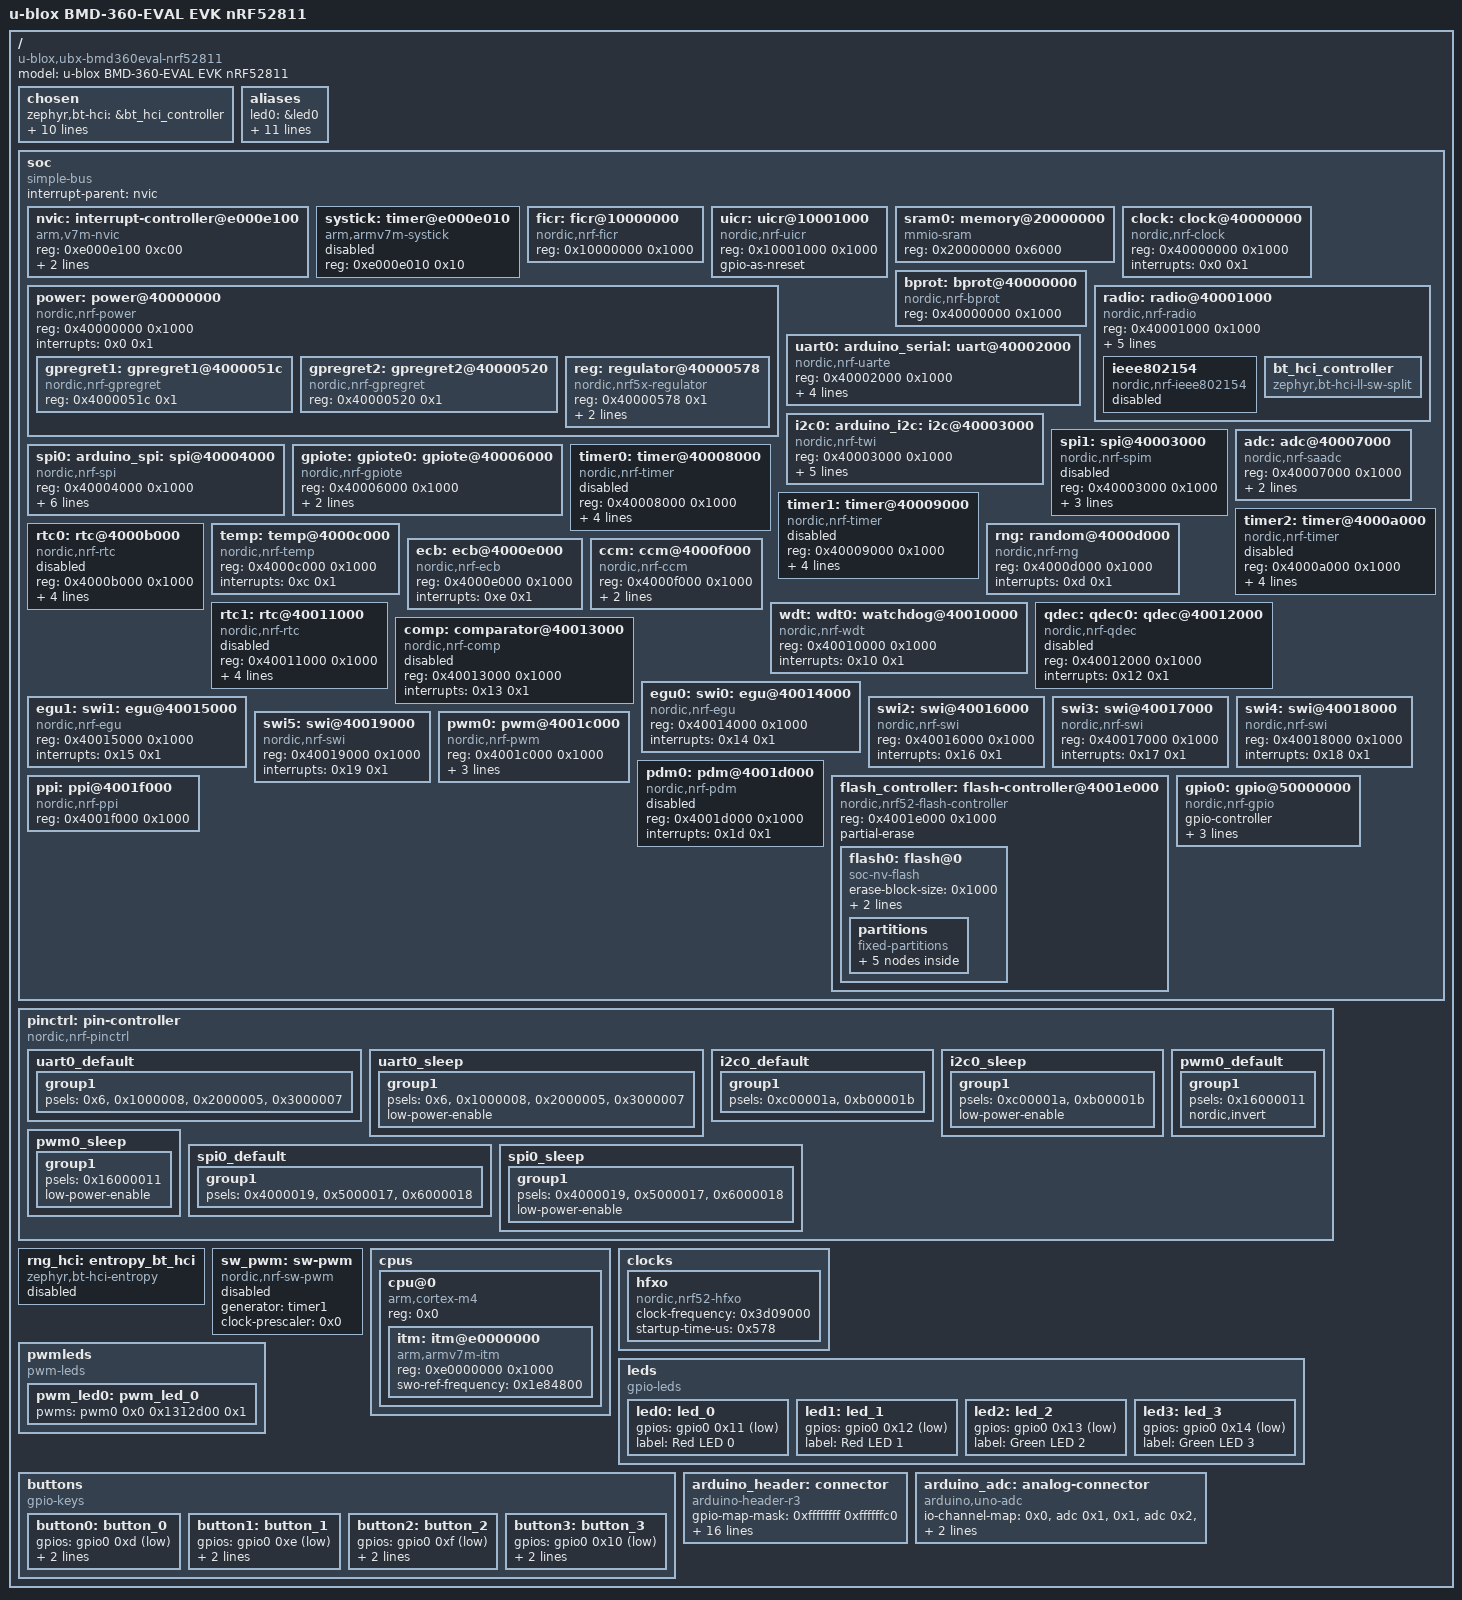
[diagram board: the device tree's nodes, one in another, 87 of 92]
/dts-v1/;

/* node '/' defined in zephyr/dts/common/skeleton.dtsi:9 */
/ {
	#address-cells = < 0x1 >;                      /* in zephyr/dts/common/skeleton.dtsi:10 */
	#size-cells = < 0x1 >;                         /* in zephyr/dts/common/skeleton.dtsi:11 */
	model = "u-blox BMD-360-EVAL EVK nRF52811";    /* in zephyr/boards/u-blox/ubx_bmd360eval/ubx_bmd360eval_nrf52811.dts:14 */
	compatible = "u-blox,ubx-bmd360eval-nrf52811"; /* in zephyr/boards/u-blox/ubx_bmd360eval/ubx_bmd360eval_nrf52811.dts:15 */

	/* node '/chosen' defined in zephyr/dts/common/skeleton.dtsi:13 */
	chosen {
		zephyr,bt-hci = &bt_hci_controller;          /* in zephyr/dts/arm/nordic/nrf52811.dtsi:14 */
		zephyr,entropy = &rng;                       /* in zephyr/dts/arm/nordic/nrf52811.dtsi:15 */
		zephyr,flash-controller = &flash_controller; /* in zephyr/dts/arm/nordic/nrf52811.dtsi:16 */
		zephyr,console = &uart0;                     /* in zephyr/boards/u-blox/ubx_bmd360eval/ubx_bmd360eval_nrf52811.dts:18 */
		zephyr,shell-uart = &uart0;                  /* in zephyr/boards/u-blox/ubx_bmd360eval/ubx_bmd360eval_nrf52811.dts:19 */
		zephyr,uart-mcumgr = &uart0;                 /* in zephyr/boards/u-blox/ubx_bmd360eval/ubx_bmd360eval_nrf52811.dts:20 */
		zephyr,bt-mon-uart = &uart0;                 /* in zephyr/boards/u-blox/ubx_bmd360eval/ubx_bmd360eval_nrf52811.dts:21 */
		zephyr,bt-c2h-uart = &uart0;                 /* in zephyr/boards/u-blox/ubx_bmd360eval/ubx_bmd360eval_nrf52811.dts:22 */
		zephyr,sram = &sram0;                        /* in zephyr/boards/u-blox/ubx_bmd360eval/ubx_bmd360eval_nrf52811.dts:23 */
		zephyr,flash = &flash0;                      /* in zephyr/boards/u-blox/ubx_bmd360eval/ubx_bmd360eval_nrf52811.dts:24 */
		zephyr,code-partition = &slot0_partition;    /* in zephyr/boards/u-blox/ubx_bmd360eval/ubx_bmd360eval_nrf52811.dts:25 */
	};

	/* node '/aliases' defined in zephyr/dts/common/skeleton.dtsi:15 */
	aliases {
		led0 = &led0;               /* in zephyr/boards/u-blox/ubx_bmd360eval/ubx_bmd360eval_nrf52811.dts:130 */
		led1 = &led1;               /* in zephyr/boards/u-blox/ubx_bmd360eval/ubx_bmd360eval_nrf52811.dts:131 */
		led2 = &led2;               /* in zephyr/boards/u-blox/ubx_bmd360eval/ubx_bmd360eval_nrf52811.dts:132 */
		led3 = &led3;               /* in zephyr/boards/u-blox/ubx_bmd360eval/ubx_bmd360eval_nrf52811.dts:133 */
		pwm-led0 = &pwm_led0;       /* in zephyr/boards/u-blox/ubx_bmd360eval/ubx_bmd360eval_nrf52811.dts:134 */
		sw0 = &button0;             /* in zephyr/boards/u-blox/ubx_bmd360eval/ubx_bmd360eval_nrf52811.dts:135 */
		sw1 = &button1;             /* in zephyr/boards/u-blox/ubx_bmd360eval/ubx_bmd360eval_nrf52811.dts:136 */
		sw2 = &button2;             /* in zephyr/boards/u-blox/ubx_bmd360eval/ubx_bmd360eval_nrf52811.dts:137 */
		sw3 = &button3;             /* in zephyr/boards/u-blox/ubx_bmd360eval/ubx_bmd360eval_nrf52811.dts:138 */
		mcuboot-button0 = &button0; /* in zephyr/boards/u-blox/ubx_bmd360eval/ubx_bmd360eval_nrf52811.dts:139 */
		mcuboot-led0 = &led0;       /* in zephyr/boards/u-blox/ubx_bmd360eval/ubx_bmd360eval_nrf52811.dts:140 */
		watchdog0 = &wdt0;          /* in zephyr/boards/u-blox/ubx_bmd360eval/ubx_bmd360eval_nrf52811.dts:141 */
	};

	/* node '/soc' defined in zephyr/dts/arm/armv7-m.dtsi:6 */
	soc {
		#address-cells = < 0x1 >;     /* in zephyr/dts/arm/armv7-m.dtsi:7 */
		#size-cells = < 0x1 >;        /* in zephyr/dts/arm/armv7-m.dtsi:8 */
		interrupt-parent = < &nvic >; /* in zephyr/dts/arm/armv7-m.dtsi:10 */
		ranges;                       /* in zephyr/dts/arm/armv7-m.dtsi:11 */
		compatible = "simple-bus";    /* in zephyr/dts/arm/nordic/nrf52811_qfaa.dtsi:21 */

		/* node '/soc/interrupt-controller@e000e100' defined in zephyr/dts/arm/armv7-m.dtsi:13 */
		nvic: interrupt-controller@e000e100 {
			#address-cells = < 0x1 >;            /* in zephyr/dts/arm/armv7-m.dtsi:14 */
			compatible = "arm,v7m-nvic";         /* in zephyr/dts/arm/armv7-m.dtsi:15 */
			reg = < 0xe000e100 0xc00 >;          /* in zephyr/dts/arm/armv7-m.dtsi:16 */
			interrupt-controller;                /* in zephyr/dts/arm/armv7-m.dtsi:17 */
			#interrupt-cells = < 0x2 >;          /* in zephyr/dts/arm/armv7-m.dtsi:18 */
			arm,num-irq-priority-bits = < 0x3 >; /* in zephyr/dts/arm/nordic/nrf52811.dtsi:411 */
			phandle = < 0x1 >;                   /* in zephyr/dts/arm/armv7-m.dtsi:10 */
		};

		/* node '/soc/timer@e000e010' defined in zephyr/dts/arm/armv7-m.dtsi:21 */
		systick: timer@e000e010 {
			compatible = "arm,armv7m-systick"; /* in zephyr/dts/arm/armv7-m.dtsi:22 */
			reg = < 0xe000e010 0x10 >;         /* in zephyr/dts/arm/armv7-m.dtsi:23 */
			status = "disabled";               /* in zephyr/dts/arm/nordic/nrf52811.dtsi:416 */
		};

		/* node '/soc/ficr@10000000' defined in zephyr/dts/arm/nordic/nrf52811.dtsi:48 */
		ficr: ficr@10000000 {
			compatible = "nordic,nrf-ficr"; /* in zephyr/dts/arm/nordic/nrf52811.dtsi:49 */
			reg = < 0x10000000 0x1000 >;    /* in zephyr/dts/arm/nordic/nrf52811.dtsi:50 */
			#nordic,ficr-cells = < 0x1 >;   /* in zephyr/dts/arm/nordic/nrf52811.dtsi:51 */
			status = "okay";                /* in zephyr/dts/arm/nordic/nrf52811.dtsi:52 */
		};

		/* node '/soc/uicr@10001000' defined in zephyr/dts/arm/nordic/nrf52811.dtsi:55 */
		uicr: uicr@10001000 {
			compatible = "nordic,nrf-uicr"; /* in zephyr/dts/arm/nordic/nrf52811.dtsi:56 */
			reg = < 0x10001000 0x1000 >;    /* in zephyr/dts/arm/nordic/nrf52811.dtsi:57 */
			status = "okay";                /* in zephyr/dts/arm/nordic/nrf52811.dtsi:58 */
			gpio-as-nreset;                 /* in zephyr/boards/u-blox/ubx_bmd360eval/ubx_bmd360eval_nrf52811.dts:154 */
		};

		/* node '/soc/memory@20000000' defined in zephyr/dts/arm/nordic/nrf52811.dtsi:61 */
		sram0: memory@20000000 {
			compatible = "mmio-sram";           /* in zephyr/dts/arm/nordic/nrf52811.dtsi:62 */
			#address-cells = < 0x1 >;           /* in zephyr/dts/arm/nordic/nrf52811.dtsi:63 */
			#size-cells = < 0x1 >;              /* in zephyr/dts/arm/nordic/nrf52811.dtsi:64 */
			reg = < 0x20000000 0x6000 >;        /* in zephyr/dts/arm/nordic/nrf52811_qfaa.dtsi:15 */
			ranges = < 0x0 0x20000000 0x6000 >; /* in zephyr/dts/arm/nordic/nrf52811_qfaa.dtsi:16 */
		};

		/* node '/soc/clock@40000000' defined in zephyr/dts/arm/nordic/nrf52811.dtsi:67 */
		clock: clock@40000000 {
			compatible = "nordic,nrf-clock"; /* in zephyr/dts/arm/nordic/nrf52811.dtsi:68 */
			reg = < 0x40000000 0x1000 >;     /* in zephyr/dts/arm/nordic/nrf52811.dtsi:69 */
			interrupts = < 0x0 0x1 >;        /* in zephyr/dts/arm/nordic/nrf52811.dtsi:70 */
			status = "okay";                 /* in zephyr/dts/arm/nordic/nrf52811.dtsi:71 */
		};

		/* node '/soc/power@40000000' defined in zephyr/dts/arm/nordic/nrf52811.dtsi:74 */
		power: power@40000000 {
			compatible = "nordic,nrf-power"; /* in zephyr/dts/arm/nordic/nrf52811.dtsi:75 */
			reg = < 0x40000000 0x1000 >;     /* in zephyr/dts/arm/nordic/nrf52811.dtsi:76 */
			interrupts = < 0x0 0x1 >;        /* in zephyr/dts/arm/nordic/nrf52811.dtsi:77 */
			status = "okay";                 /* in zephyr/dts/arm/nordic/nrf52811.dtsi:78 */
			#address-cells = < 0x1 >;        /* in zephyr/dts/arm/nordic/nrf52811.dtsi:79 */
			#size-cells = < 0x1 >;           /* in zephyr/dts/arm/nordic/nrf52811.dtsi:80 */

			/* node '/soc/power@40000000/gpregret1@4000051c' defined in zephyr/dts/arm/nordic/nrf52811.dtsi:82 */
			gpregret1: gpregret1@4000051c {
				#address-cells = < 0x1 >;           /* in zephyr/dts/arm/nordic/nrf52811.dtsi:83 */
				#size-cells = < 0x1 >;              /* in zephyr/dts/arm/nordic/nrf52811.dtsi:84 */
				compatible = "nordic,nrf-gpregret"; /* in zephyr/dts/arm/nordic/nrf52811.dtsi:85 */
				reg = < 0x4000051c 0x1 >;           /* in zephyr/dts/arm/nordic/nrf52811.dtsi:86 */
				status = "okay";                    /* in zephyr/dts/arm/nordic/nrf52811.dtsi:87 */
			};

			/* node '/soc/power@40000000/gpregret2@40000520' defined in zephyr/dts/arm/nordic/nrf52811.dtsi:90 */
			gpregret2: gpregret2@40000520 {
				#address-cells = < 0x1 >;           /* in zephyr/dts/arm/nordic/nrf52811.dtsi:91 */
				#size-cells = < 0x1 >;              /* in zephyr/dts/arm/nordic/nrf52811.dtsi:92 */
				compatible = "nordic,nrf-gpregret"; /* in zephyr/dts/arm/nordic/nrf52811.dtsi:93 */
				reg = < 0x40000520 0x1 >;           /* in zephyr/dts/arm/nordic/nrf52811.dtsi:94 */
				status = "okay";                    /* in zephyr/dts/arm/nordic/nrf52811.dtsi:95 */
			};

			/* node '/soc/power@40000000/regulator@40000578' defined in zephyr/dts/arm/nordic/nrf52811.dtsi:98 */
			reg: regulator@40000578 {
				compatible = "nordic,nrf5x-regulator"; /* in zephyr/dts/arm/nordic/nrf52811.dtsi:99 */
				reg = < 0x40000578 0x1 >;              /* in zephyr/dts/arm/nordic/nrf52811.dtsi:100 */
				regulator-name = "REG";                /* in zephyr/dts/arm/nordic/nrf52811.dtsi:101 */
				regulator-initial-mode = < 0x1 >;      /* in zephyr/boards/u-blox/ubx_bmd360eval/ubx_bmd360eval_nrf52811.dts:146 */
			};
		};

		/* node '/soc/bprot@40000000' defined in zephyr/dts/arm/nordic/nrf52811.dtsi:106 */
		bprot: bprot@40000000 {
			compatible = "nordic,nrf-bprot"; /* in zephyr/dts/arm/nordic/nrf52811.dtsi:107 */
			reg = < 0x40000000 0x1000 >;     /* in zephyr/dts/arm/nordic/nrf52811.dtsi:108 */
			status = "okay";                 /* in zephyr/dts/arm/nordic/nrf52811.dtsi:109 */
		};

		/* node '/soc/radio@40001000' defined in zephyr/dts/arm/nordic/nrf52811.dtsi:112 */
		radio: radio@40001000 {
			compatible = "nordic,nrf-radio"; /* in zephyr/dts/arm/nordic/nrf52811.dtsi:113 */
			reg = < 0x40001000 0x1000 >;     /* in zephyr/dts/arm/nordic/nrf52811.dtsi:114 */
			interrupts = < 0x1 0x1 >;        /* in zephyr/dts/arm/nordic/nrf52811.dtsi:115 */
			status = "okay";                 /* in zephyr/dts/arm/nordic/nrf52811.dtsi:116 */
			dfe-supported;                   /* in zephyr/dts/arm/nordic/nrf52811.dtsi:117 */
			ieee802154-supported;            /* in zephyr/dts/arm/nordic/nrf52811.dtsi:118 */
			ble-2mbps-supported;             /* in zephyr/dts/arm/nordic/nrf52811.dtsi:119 */
			ble-coded-phy-supported;         /* in zephyr/dts/arm/nordic/nrf52811.dtsi:120 */

			/* node '/soc/radio@40001000/ieee802154' defined in zephyr/dts/arm/nordic/nrf52811.dtsi:122 */
			ieee802154: ieee802154 {
				compatible = "nordic,nrf-ieee802154"; /* in zephyr/dts/arm/nordic/nrf52811.dtsi:123 */
				status = "disabled";                  /* in zephyr/dts/arm/nordic/nrf52811.dtsi:124 */
			};

			/* node '/soc/radio@40001000/bt_hci_controller' defined in zephyr/dts/arm/nordic/nrf52811.dtsi:130 */
			bt_hci_controller: bt_hci_controller {
				compatible = "zephyr,bt-hci-ll-sw-split"; /* in zephyr/dts/arm/nordic/nrf52811.dtsi:131 */
				status = "okay";                          /* in zephyr/dts/arm/nordic/nrf52811.dtsi:132 */
			};
		};

		/* node '/soc/uart@40002000' defined in zephyr/dts/arm/nordic/nrf52811.dtsi:136 */
		uart0: arduino_serial: uart@40002000 {
			reg = < 0x40002000 0x1000 >;     /* in zephyr/dts/arm/nordic/nrf52811.dtsi:140 */
			interrupts = < 0x2 0x1 >;        /* in zephyr/dts/arm/nordic/nrf52811.dtsi:141 */
			compatible = "nordic,nrf-uarte"; /* in zephyr/boards/u-blox/ubx_bmd360eval/ubx_bmd360eval_nrf52811.dts:166 */
			status = "okay";                 /* in zephyr/boards/u-blox/ubx_bmd360eval/ubx_bmd360eval_nrf52811.dts:167 */
			current-speed = < 0x1c200 >;     /* in zephyr/boards/u-blox/ubx_bmd360eval/ubx_bmd360eval_nrf52811.dts:168 */
			pinctrl-0 = < &uart0_default >;  /* in zephyr/boards/u-blox/ubx_bmd360eval/ubx_bmd360eval_nrf52811.dts:169 */
			pinctrl-1 = < &uart0_sleep >;    /* in zephyr/boards/u-blox/ubx_bmd360eval/ubx_bmd360eval_nrf52811.dts:170 */
			pinctrl-names = "default",
			                "sleep";         /* in zephyr/boards/u-blox/ubx_bmd360eval/ubx_bmd360eval_nrf52811.dts:171 */
		};

		/* node '/soc/i2c@40003000' defined in zephyr/dts/arm/nordic/nrf52811.dtsi:145 */
		i2c0: arduino_i2c: i2c@40003000 {
			#address-cells = < 0x1 >;      /* in zephyr/dts/arm/nordic/nrf52811.dtsi:154 */
			#size-cells = < 0x0 >;         /* in zephyr/dts/arm/nordic/nrf52811.dtsi:155 */
			reg = < 0x40003000 0x1000 >;   /* in zephyr/dts/arm/nordic/nrf52811.dtsi:156 */
			interrupts = < 0x3 0x1 >;      /* in zephyr/dts/arm/nordic/nrf52811.dtsi:157 */
			easydma-maxcnt-bits = < 0xe >; /* in zephyr/dts/arm/nordic/nrf52811.dtsi:158 */
			zephyr,pm-device-runtime-auto; /* in zephyr/dts/arm/nordic/nrf52811.dtsi:160 */
			compatible = "nordic,nrf-twi"; /* in zephyr/boards/u-blox/ubx_bmd360eval/ubx_bmd360eval_nrf52811.dts:175 */
			status = "okay";               /* in zephyr/boards/u-blox/ubx_bmd360eval/ubx_bmd360eval_nrf52811.dts:176 */
			pinctrl-0 = < &i2c0_default >; /* in zephyr/boards/u-blox/ubx_bmd360eval/ubx_bmd360eval_nrf52811.dts:178 */
			pinctrl-1 = < &i2c0_sleep >;   /* in zephyr/boards/u-blox/ubx_bmd360eval/ubx_bmd360eval_nrf52811.dts:179 */
			pinctrl-names = "default",
			                "sleep";       /* in zephyr/boards/u-blox/ubx_bmd360eval/ubx_bmd360eval_nrf52811.dts:180 */
		};

		/* node '/soc/spi@40003000' defined in zephyr/dts/arm/nordic/nrf52811.dtsi:163 */
		spi1: spi@40003000 {
			compatible = "nordic,nrf-spim"; /* in zephyr/dts/arm/nordic/nrf52811.dtsi:172 */
			#address-cells = < 0x1 >;       /* in zephyr/dts/arm/nordic/nrf52811.dtsi:173 */
			#size-cells = < 0x0 >;          /* in zephyr/dts/arm/nordic/nrf52811.dtsi:174 */
			reg = < 0x40003000 0x1000 >;    /* in zephyr/dts/arm/nordic/nrf52811.dtsi:175 */
			interrupts = < 0x3 0x1 >;       /* in zephyr/dts/arm/nordic/nrf52811.dtsi:176 */
			max-frequency = < 0x7a1200 >;   /* in zephyr/dts/arm/nordic/nrf52811.dtsi:177 */
			easydma-maxcnt-bits = < 0xe >;  /* in zephyr/dts/arm/nordic/nrf52811.dtsi:178 */
			status = "disabled";            /* in zephyr/dts/arm/nordic/nrf52811.dtsi:179 */
		};

		/* node '/soc/spi@40004000' defined in zephyr/dts/arm/nordic/nrf52811.dtsi:182 */
		spi0: arduino_spi: spi@40004000 {
			#address-cells = < 0x1 >;                /* in zephyr/dts/arm/nordic/nrf52811.dtsi:191 */
			#size-cells = < 0x0 >;                   /* in zephyr/dts/arm/nordic/nrf52811.dtsi:192 */
			reg = < 0x40004000 0x1000 >;             /* in zephyr/dts/arm/nordic/nrf52811.dtsi:193 */
			interrupts = < 0x4 0x1 >;                /* in zephyr/dts/arm/nordic/nrf52811.dtsi:194 */
			max-frequency = < 0x7a1200 >;            /* in zephyr/dts/arm/nordic/nrf52811.dtsi:195 */
			easydma-maxcnt-bits = < 0xe >;           /* in zephyr/dts/arm/nordic/nrf52811.dtsi:196 */
			compatible = "nordic,nrf-spi";           /* in zephyr/boards/u-blox/ubx_bmd360eval/ubx_bmd360eval_nrf52811.dts:191 */
			status = "okay";                         /* in zephyr/boards/u-blox/ubx_bmd360eval/ubx_bmd360eval_nrf52811.dts:192 */
			cs-gpios = < &arduino_header 0x10 0x1 >; /* in zephyr/boards/u-blox/ubx_bmd360eval/ubx_bmd360eval_nrf52811.dts:193 */
			pinctrl-0 = < &spi0_default >;           /* in zephyr/boards/u-blox/ubx_bmd360eval/ubx_bmd360eval_nrf52811.dts:194 */
			pinctrl-1 = < &spi0_sleep >;             /* in zephyr/boards/u-blox/ubx_bmd360eval/ubx_bmd360eval_nrf52811.dts:195 */
			pinctrl-names = "default",
			                "sleep";                 /* in zephyr/boards/u-blox/ubx_bmd360eval/ubx_bmd360eval_nrf52811.dts:196 */
		};

		/* node '/soc/gpiote@40006000' defined in zephyr/dts/arm/nordic/nrf52811.dtsi:200 */
		gpiote: gpiote0: gpiote@40006000 {
			compatible = "nordic,nrf-gpiote"; /* in zephyr/dts/arm/nordic/nrf52811.dtsi:201 */
			reg = < 0x40006000 0x1000 >;      /* in zephyr/dts/arm/nordic/nrf52811.dtsi:202 */
			interrupts = < 0x6 0x5 >;         /* in zephyr/dts/arm/nordic/nrf52811.dtsi:203 */
			instance = < 0x0 >;               /* in zephyr/dts/arm/nordic/nrf52811.dtsi:205 */
			status = "okay";                  /* in zephyr/boards/u-blox/ubx_bmd360eval/ubx_bmd360eval_nrf52811.dts:158 */
			phandle = < 0xb >;                /* in zephyr/dts/arm/nordic/nrf52811.dtsi:405 */
		};

		/* node '/soc/adc@40007000' defined in zephyr/dts/arm/nordic/nrf52811.dtsi:208 */
		adc: adc@40007000 {
			compatible = "nordic,nrf-saadc"; /* in zephyr/dts/arm/nordic/nrf52811.dtsi:209 */
			reg = < 0x40007000 0x1000 >;     /* in zephyr/dts/arm/nordic/nrf52811.dtsi:210 */
			interrupts = < 0x7 0x1 >;        /* in zephyr/dts/arm/nordic/nrf52811.dtsi:211 */
			#io-channel-cells = < 0x1 >;     /* in zephyr/dts/arm/nordic/nrf52811.dtsi:213 */
			zephyr,pm-device-runtime-auto;   /* in zephyr/dts/arm/nordic/nrf52811.dtsi:214 */
			status = "okay";                 /* in zephyr/boards/u-blox/ubx_bmd360eval/ubx_bmd360eval_nrf52811.dts:150 */
			phandle = < 0xf >;               /* in zephyr/boards/u-blox/ubx_bmd360eval/ubx_bmd360eval_nrf52811.dts:120 */
		};

		/* node '/soc/timer@40008000' defined in zephyr/dts/arm/nordic/nrf52811.dtsi:217 */
		timer0: timer@40008000 {
			compatible = "nordic,nrf-timer"; /* in zephyr/dts/arm/nordic/nrf52811.dtsi:218 */
			status = "disabled";             /* in zephyr/dts/arm/nordic/nrf52811.dtsi:219 */
			reg = < 0x40008000 0x1000 >;     /* in zephyr/dts/arm/nordic/nrf52811.dtsi:220 */
			cc-num = < 0x4 >;                /* in zephyr/dts/arm/nordic/nrf52811.dtsi:221 */
			max-bit-width = < 0x20 >;        /* in zephyr/dts/arm/nordic/nrf52811.dtsi:222 */
			interrupts = < 0x8 0x1 >;        /* in zephyr/dts/arm/nordic/nrf52811.dtsi:223 */
			prescaler = < 0x0 >;             /* in zephyr/dts/arm/nordic/nrf52811.dtsi:224 */
		};

		/* node '/soc/timer@40009000' defined in zephyr/dts/arm/nordic/nrf52811.dtsi:227 */
		timer1: timer@40009000 {
			compatible = "nordic,nrf-timer"; /* in zephyr/dts/arm/nordic/nrf52811.dtsi:228 */
			status = "disabled";             /* in zephyr/dts/arm/nordic/nrf52811.dtsi:229 */
			reg = < 0x40009000 0x1000 >;     /* in zephyr/dts/arm/nordic/nrf52811.dtsi:230 */
			cc-num = < 0x4 >;                /* in zephyr/dts/arm/nordic/nrf52811.dtsi:231 */
			max-bit-width = < 0x20 >;        /* in zephyr/dts/arm/nordic/nrf52811.dtsi:232 */
			interrupts = < 0x9 0x1 >;        /* in zephyr/dts/arm/nordic/nrf52811.dtsi:233 */
			prescaler = < 0x0 >;             /* in zephyr/dts/arm/nordic/nrf52811.dtsi:234 */
			phandle = < 0xc >;               /* in zephyr/dts/vendor/nordic/nrf_common.dtsi:42 */
		};

		/* node '/soc/timer@4000a000' defined in zephyr/dts/arm/nordic/nrf52811.dtsi:237 */
		timer2: timer@4000a000 {
			compatible = "nordic,nrf-timer"; /* in zephyr/dts/arm/nordic/nrf52811.dtsi:238 */
			status = "disabled";             /* in zephyr/dts/arm/nordic/nrf52811.dtsi:239 */
			reg = < 0x4000a000 0x1000 >;     /* in zephyr/dts/arm/nordic/nrf52811.dtsi:240 */
			cc-num = < 0x4 >;                /* in zephyr/dts/arm/nordic/nrf52811.dtsi:241 */
			max-bit-width = < 0x20 >;        /* in zephyr/dts/arm/nordic/nrf52811.dtsi:242 */
			interrupts = < 0xa 0x1 >;        /* in zephyr/dts/arm/nordic/nrf52811.dtsi:243 */
			prescaler = < 0x0 >;             /* in zephyr/dts/arm/nordic/nrf52811.dtsi:244 */
		};

		/* node '/soc/rtc@4000b000' defined in zephyr/dts/arm/nordic/nrf52811.dtsi:247 */
		rtc0: rtc@4000b000 {
			compatible = "nordic,nrf-rtc"; /* in zephyr/dts/arm/nordic/nrf52811.dtsi:248 */
			reg = < 0x4000b000 0x1000 >;   /* in zephyr/dts/arm/nordic/nrf52811.dtsi:249 */
			cc-num = < 0x3 >;              /* in zephyr/dts/arm/nordic/nrf52811.dtsi:250 */
			interrupts = < 0xb 0x1 >;      /* in zephyr/dts/arm/nordic/nrf52811.dtsi:251 */
			status = "disabled";           /* in zephyr/dts/arm/nordic/nrf52811.dtsi:252 */
			clock-frequency = < 0x8000 >;  /* in zephyr/dts/arm/nordic/nrf52811.dtsi:253 */
			prescaler = < 0x1 >;           /* in zephyr/dts/arm/nordic/nrf52811.dtsi:254 */
		};

		/* node '/soc/temp@4000c000' defined in zephyr/dts/arm/nordic/nrf52811.dtsi:257 */
		temp: temp@4000c000 {
			compatible = "nordic,nrf-temp"; /* in zephyr/dts/arm/nordic/nrf52811.dtsi:258 */
			reg = < 0x4000c000 0x1000 >;    /* in zephyr/dts/arm/nordic/nrf52811.dtsi:259 */
			interrupts = < 0xc 0x1 >;       /* in zephyr/dts/arm/nordic/nrf52811.dtsi:260 */
			status = "okay";                /* in zephyr/dts/arm/nordic/nrf52811.dtsi:261 */
		};

		/* node '/soc/random@4000d000' defined in zephyr/dts/arm/nordic/nrf52811.dtsi:264 */
		rng: random@4000d000 {
			compatible = "nordic,nrf-rng"; /* in zephyr/dts/arm/nordic/nrf52811.dtsi:265 */
			reg = < 0x4000d000 0x1000 >;   /* in zephyr/dts/arm/nordic/nrf52811.dtsi:266 */
			interrupts = < 0xd 0x1 >;      /* in zephyr/dts/arm/nordic/nrf52811.dtsi:267 */
			status = "okay";               /* in zephyr/dts/arm/nordic/nrf52811.dtsi:268 */
		};

		/* node '/soc/ecb@4000e000' defined in zephyr/dts/arm/nordic/nrf52811.dtsi:271 */
		ecb: ecb@4000e000 {
			compatible = "nordic,nrf-ecb"; /* in zephyr/dts/arm/nordic/nrf52811.dtsi:272 */
			reg = < 0x4000e000 0x1000 >;   /* in zephyr/dts/arm/nordic/nrf52811.dtsi:273 */
			interrupts = < 0xe 0x1 >;      /* in zephyr/dts/arm/nordic/nrf52811.dtsi:274 */
			status = "okay";               /* in zephyr/dts/arm/nordic/nrf52811.dtsi:275 */
		};

		/* node '/soc/ccm@4000f000' defined in zephyr/dts/arm/nordic/nrf52811.dtsi:278 */
		ccm: ccm@4000f000 {
			compatible = "nordic,nrf-ccm"; /* in zephyr/dts/arm/nordic/nrf52811.dtsi:279 */
			reg = < 0x4000f000 0x1000 >;   /* in zephyr/dts/arm/nordic/nrf52811.dtsi:280 */
			interrupts = < 0xf 0x1 >;      /* in zephyr/dts/arm/nordic/nrf52811.dtsi:281 */
			length-field-length-8-bits;    /* in zephyr/dts/arm/nordic/nrf52811.dtsi:282 */
			status = "okay";               /* in zephyr/dts/arm/nordic/nrf52811.dtsi:283 */
		};

		/* node '/soc/watchdog@40010000' defined in zephyr/dts/arm/nordic/nrf52811.dtsi:286 */
		wdt: wdt0: watchdog@40010000 {
			compatible = "nordic,nrf-wdt"; /* in zephyr/dts/arm/nordic/nrf52811.dtsi:287 */
			reg = < 0x40010000 0x1000 >;   /* in zephyr/dts/arm/nordic/nrf52811.dtsi:288 */
			interrupts = < 0x10 0x1 >;     /* in zephyr/dts/arm/nordic/nrf52811.dtsi:289 */
			status = "okay";               /* in zephyr/dts/arm/nordic/nrf52811.dtsi:290 */
		};

		/* node '/soc/rtc@40011000' defined in zephyr/dts/arm/nordic/nrf52811.dtsi:293 */
		rtc1: rtc@40011000 {
			compatible = "nordic,nrf-rtc"; /* in zephyr/dts/arm/nordic/nrf52811.dtsi:294 */
			reg = < 0x40011000 0x1000 >;   /* in zephyr/dts/arm/nordic/nrf52811.dtsi:295 */
			cc-num = < 0x4 >;              /* in zephyr/dts/arm/nordic/nrf52811.dtsi:296 */
			interrupts = < 0x11 0x1 >;     /* in zephyr/dts/arm/nordic/nrf52811.dtsi:297 */
			status = "disabled";           /* in zephyr/dts/arm/nordic/nrf52811.dtsi:298 */
			clock-frequency = < 0x8000 >;  /* in zephyr/dts/arm/nordic/nrf52811.dtsi:299 */
			prescaler = < 0x1 >;           /* in zephyr/dts/arm/nordic/nrf52811.dtsi:300 */
		};

		/* node '/soc/qdec@40012000' defined in zephyr/dts/arm/nordic/nrf52811.dtsi:303 */
		qdec: qdec0: qdec@40012000 {
			compatible = "nordic,nrf-qdec"; /* in zephyr/dts/arm/nordic/nrf52811.dtsi:304 */
			reg = < 0x40012000 0x1000 >;    /* in zephyr/dts/arm/nordic/nrf52811.dtsi:305 */
			interrupts = < 0x12 0x1 >;      /* in zephyr/dts/arm/nordic/nrf52811.dtsi:306 */
			status = "disabled";            /* in zephyr/dts/arm/nordic/nrf52811.dtsi:307 */
		};

		/* node '/soc/comparator@40013000' defined in zephyr/dts/arm/nordic/nrf52811.dtsi:310 */
		comp: comparator@40013000 {
			compatible = "nordic,nrf-comp"; /* in zephyr/dts/arm/nordic/nrf52811.dtsi:311 */
			reg = < 0x40013000 0x1000 >;    /* in zephyr/dts/arm/nordic/nrf52811.dtsi:312 */
			interrupts = < 0x13 0x1 >;      /* in zephyr/dts/arm/nordic/nrf52811.dtsi:313 */
			status = "disabled";            /* in zephyr/dts/arm/nordic/nrf52811.dtsi:314 */
		};

		/* node '/soc/egu@40014000' defined in zephyr/dts/arm/nordic/nrf52811.dtsi:317 */
		egu0: swi0: egu@40014000 {
			compatible = "nordic,nrf-egu",
			             "nordic,nrf-swi"; /* in zephyr/dts/arm/nordic/nrf52811.dtsi:318 */
			reg = < 0x40014000 0x1000 >;   /* in zephyr/dts/arm/nordic/nrf52811.dtsi:319 */
			interrupts = < 0x14 0x1 >;     /* in zephyr/dts/arm/nordic/nrf52811.dtsi:320 */
			status = "okay";               /* in zephyr/dts/arm/nordic/nrf52811.dtsi:321 */
		};

		/* node '/soc/egu@40015000' defined in zephyr/dts/arm/nordic/nrf52811.dtsi:324 */
		egu1: swi1: egu@40015000 {
			compatible = "nordic,nrf-egu",
			             "nordic,nrf-swi"; /* in zephyr/dts/arm/nordic/nrf52811.dtsi:325 */
			reg = < 0x40015000 0x1000 >;   /* in zephyr/dts/arm/nordic/nrf52811.dtsi:326 */
			interrupts = < 0x15 0x1 >;     /* in zephyr/dts/arm/nordic/nrf52811.dtsi:327 */
			status = "okay";               /* in zephyr/dts/arm/nordic/nrf52811.dtsi:328 */
		};

		/* node '/soc/swi@40016000' defined in zephyr/dts/arm/nordic/nrf52811.dtsi:331 */
		swi2: swi@40016000 {
			compatible = "nordic,nrf-swi"; /* in zephyr/dts/arm/nordic/nrf52811.dtsi:332 */
			reg = < 0x40016000 0x1000 >;   /* in zephyr/dts/arm/nordic/nrf52811.dtsi:333 */
			interrupts = < 0x16 0x1 >;     /* in zephyr/dts/arm/nordic/nrf52811.dtsi:334 */
			status = "okay";               /* in zephyr/dts/arm/nordic/nrf52811.dtsi:335 */
		};

		/* node '/soc/swi@40017000' defined in zephyr/dts/arm/nordic/nrf52811.dtsi:338 */
		swi3: swi@40017000 {
			compatible = "nordic,nrf-swi"; /* in zephyr/dts/arm/nordic/nrf52811.dtsi:339 */
			reg = < 0x40017000 0x1000 >;   /* in zephyr/dts/arm/nordic/nrf52811.dtsi:340 */
			interrupts = < 0x17 0x1 >;     /* in zephyr/dts/arm/nordic/nrf52811.dtsi:341 */
			status = "okay";               /* in zephyr/dts/arm/nordic/nrf52811.dtsi:342 */
		};

		/* node '/soc/swi@40018000' defined in zephyr/dts/arm/nordic/nrf52811.dtsi:345 */
		swi4: swi@40018000 {
			compatible = "nordic,nrf-swi"; /* in zephyr/dts/arm/nordic/nrf52811.dtsi:346 */
			reg = < 0x40018000 0x1000 >;   /* in zephyr/dts/arm/nordic/nrf52811.dtsi:347 */
			interrupts = < 0x18 0x1 >;     /* in zephyr/dts/arm/nordic/nrf52811.dtsi:348 */
			status = "okay";               /* in zephyr/dts/arm/nordic/nrf52811.dtsi:349 */
		};

		/* node '/soc/swi@40019000' defined in zephyr/dts/arm/nordic/nrf52811.dtsi:352 */
		swi5: swi@40019000 {
			compatible = "nordic,nrf-swi"; /* in zephyr/dts/arm/nordic/nrf52811.dtsi:353 */
			reg = < 0x40019000 0x1000 >;   /* in zephyr/dts/arm/nordic/nrf52811.dtsi:354 */
			interrupts = < 0x19 0x1 >;     /* in zephyr/dts/arm/nordic/nrf52811.dtsi:355 */
			status = "okay";               /* in zephyr/dts/arm/nordic/nrf52811.dtsi:356 */
		};

		/* node '/soc/pwm@4001c000' defined in zephyr/dts/arm/nordic/nrf52811.dtsi:359 */
		pwm0: pwm@4001c000 {
			compatible = "nordic,nrf-pwm"; /* in zephyr/dts/arm/nordic/nrf52811.dtsi:360 */
			reg = < 0x4001c000 0x1000 >;   /* in zephyr/dts/arm/nordic/nrf52811.dtsi:361 */
			interrupts = < 0x1c 0x1 >;     /* in zephyr/dts/arm/nordic/nrf52811.dtsi:362 */
			#pwm-cells = < 0x3 >;          /* in zephyr/dts/arm/nordic/nrf52811.dtsi:364 */
			status = "okay";               /* in zephyr/boards/u-blox/ubx_bmd360eval/ubx_bmd360eval_nrf52811.dts:184 */
			pinctrl-0 = < &pwm0_default >; /* in zephyr/boards/u-blox/ubx_bmd360eval/ubx_bmd360eval_nrf52811.dts:185 */
			pinctrl-1 = < &pwm0_sleep >;   /* in zephyr/boards/u-blox/ubx_bmd360eval/ubx_bmd360eval_nrf52811.dts:186 */
			pinctrl-names = "default",
			                "sleep";       /* in zephyr/boards/u-blox/ubx_bmd360eval/ubx_bmd360eval_nrf52811.dts:187 */
			phandle = < 0xe >;             /* in zephyr/boards/u-blox/ubx_bmd360eval/ubx_bmd360eval_nrf52811.dts:56 */
		};

		/* node '/soc/pdm@4001d000' defined in zephyr/dts/arm/nordic/nrf52811.dtsi:367 */
		pdm0: pdm@4001d000 {
			compatible = "nordic,nrf-pdm"; /* in zephyr/dts/arm/nordic/nrf52811.dtsi:368 */
			reg = < 0x4001d000 0x1000 >;   /* in zephyr/dts/arm/nordic/nrf52811.dtsi:369 */
			interrupts = < 0x1d 0x1 >;     /* in zephyr/dts/arm/nordic/nrf52811.dtsi:370 */
			status = "disabled";           /* in zephyr/dts/arm/nordic/nrf52811.dtsi:371 */
		};

		/* node '/soc/flash-controller@4001e000' defined in zephyr/dts/arm/nordic/nrf52811.dtsi:374 */
		flash_controller: flash-controller@4001e000 {
			compatible = "nordic,nrf52-flash-controller"; /* in zephyr/dts/arm/nordic/nrf52811.dtsi:375 */
			reg = < 0x4001e000 0x1000 >;                  /* in zephyr/dts/arm/nordic/nrf52811.dtsi:376 */
			partial-erase;                                /* in zephyr/dts/arm/nordic/nrf52811.dtsi:377 */
			#address-cells = < 0x1 >;                     /* in zephyr/dts/arm/nordic/nrf52811.dtsi:379 */
			#size-cells = < 0x1 >;                        /* in zephyr/dts/arm/nordic/nrf52811.dtsi:380 */

			/* node '/soc/flash-controller@4001e000/flash@0' defined in zephyr/dts/arm/nordic/nrf52811.dtsi:382 */
			flash0: flash@0 {
				compatible = "soc-nv-flash";   /* in zephyr/dts/arm/nordic/nrf52811.dtsi:383 */
				erase-block-size = < 0x1000 >; /* in zephyr/dts/arm/nordic/nrf52811.dtsi:384 */
				write-block-size = < 0x4 >;    /* in zephyr/dts/arm/nordic/nrf52811.dtsi:385 */
				reg = < 0x0 0x30000 >;         /* in zephyr/dts/arm/nordic/nrf52811_qfaa.dtsi:11 */

				/* node '/soc/flash-controller@4001e000/flash@0/partitions' defined in zephyr/boards/u-blox/ubx_bmd360eval/ubx_bmd360eval_nrf52811.dts:200 */
				partitions {
					compatible = "fixed-partitions"; /* in zephyr/boards/u-blox/ubx_bmd360eval/ubx_bmd360eval_nrf52811.dts:201 */
					#address-cells = < 0x1 >;        /* in zephyr/boards/u-blox/ubx_bmd360eval/ubx_bmd360eval_nrf52811.dts:202 */
					#size-cells = < 0x1 >;           /* in zephyr/boards/u-blox/ubx_bmd360eval/ubx_bmd360eval_nrf52811.dts:203 */

					/* node '/soc/flash-controller@4001e000/flash@0/partitions/partition@0' defined in zephyr/boards/u-blox/ubx_bmd360eval/ubx_bmd360eval_nrf52811.dts:205 */
					boot_partition: partition@0 {
						label = "mcuboot";    /* in zephyr/boards/u-blox/ubx_bmd360eval/ubx_bmd360eval_nrf52811.dts:206 */
						reg = < 0x0 0xc000 >; /* in zephyr/boards/u-blox/ubx_bmd360eval/ubx_bmd360eval_nrf52811.dts:207 */
					};

					/* node '/soc/flash-controller@4001e000/flash@0/partitions/partition@c000' defined in zephyr/boards/u-blox/ubx_bmd360eval/ubx_bmd360eval_nrf52811.dts:210 */
					slot0_partition: partition@c000 {
						label = "image-0";       /* in zephyr/boards/u-blox/ubx_bmd360eval/ubx_bmd360eval_nrf52811.dts:211 */
						reg = < 0xc000 0xd000 >; /* in zephyr/boards/u-blox/ubx_bmd360eval/ubx_bmd360eval_nrf52811.dts:212 */
					};

					/* node '/soc/flash-controller@4001e000/flash@0/partitions/partition@19000' defined in zephyr/boards/u-blox/ubx_bmd360eval/ubx_bmd360eval_nrf52811.dts:215 */
					slot1_partition: partition@19000 {
						label = "image-1";        /* in zephyr/boards/u-blox/ubx_bmd360eval/ubx_bmd360eval_nrf52811.dts:216 */
						reg = < 0x19000 0xd000 >; /* in zephyr/boards/u-blox/ubx_bmd360eval/ubx_bmd360eval_nrf52811.dts:217 */
					};

					/* node '/soc/flash-controller@4001e000/flash@0/partitions/partition@26000' defined in zephyr/boards/u-blox/ubx_bmd360eval/ubx_bmd360eval_nrf52811.dts:220 */
					scratch_partition: partition@26000 {
						label = "image-scratch";  /* in zephyr/boards/u-blox/ubx_bmd360eval/ubx_bmd360eval_nrf52811.dts:221 */
						reg = < 0x26000 0x3000 >; /* in zephyr/boards/u-blox/ubx_bmd360eval/ubx_bmd360eval_nrf52811.dts:222 */
					};

					/* node '/soc/flash-controller@4001e000/flash@0/partitions/partition@29000' defined in zephyr/boards/u-blox/ubx_bmd360eval/ubx_bmd360eval_nrf52811.dts:225 */
					storage_partition: partition@29000 {
						label = "storage";        /* in zephyr/boards/u-blox/ubx_bmd360eval/ubx_bmd360eval_nrf52811.dts:226 */
						reg = < 0x29000 0x7000 >; /* in zephyr/boards/u-blox/ubx_bmd360eval/ubx_bmd360eval_nrf52811.dts:227 */
					};
				};
			};
		};

		/* node '/soc/ppi@4001f000' defined in zephyr/dts/arm/nordic/nrf52811.dtsi:389 */
		ppi: ppi@4001f000 {
			compatible = "nordic,nrf-ppi"; /* in zephyr/dts/arm/nordic/nrf52811.dtsi:390 */
			reg = < 0x4001f000 0x1000 >;   /* in zephyr/dts/arm/nordic/nrf52811.dtsi:391 */
			status = "okay";               /* in zephyr/dts/arm/nordic/nrf52811.dtsi:392 */
		};

		/* node '/soc/gpio@50000000' defined in zephyr/dts/arm/nordic/nrf52811.dtsi:395 */
		gpio0: gpio@50000000 {
			compatible = "nordic,nrf-gpio";              /* in zephyr/dts/arm/nordic/nrf52811.dtsi:396 */
			gpio-controller;                             /* in zephyr/dts/arm/nordic/nrf52811.dtsi:397 */
			reg = < 0x50000000 0x200 0x50000500 0x300 >; /* in zephyr/dts/arm/nordic/nrf52811.dtsi:400 */
			#gpio-cells = < 0x2 >;                       /* in zephyr/dts/arm/nordic/nrf52811.dtsi:402 */
			port = < 0x0 >;                              /* in zephyr/dts/arm/nordic/nrf52811.dtsi:404 */
			gpiote-instance = < &gpiote >;               /* in zephyr/dts/arm/nordic/nrf52811.dtsi:405 */
			status = "okay";                             /* in zephyr/boards/u-blox/ubx_bmd360eval/ubx_bmd360eval_nrf52811.dts:162 */
			phandle = < 0xd >;                           /* in zephyr/boards/u-blox/ubx_bmd360eval/ubx_bmd360eval_nrf52811.dts:32 */
		};
	};

	/* node '/pin-controller' defined in zephyr/dts/vendor/nordic/nrf_common.dtsi:26 */
	pinctrl: pin-controller {
		compatible = "nordic,nrf-pinctrl"; /* in zephyr/dts/vendor/nordic/nrf_common.dtsi:31 */

		/* node '/pin-controller/uart0_default' defined in zephyr/boards/u-blox/ubx_bmd360eval/ubx_bmd360eval_nrf52811-pinctrl.dtsi:7 */
		uart0_default: uart0_default {
			phandle = < 0x2 >; /* in zephyr/boards/u-blox/ubx_bmd360eval/ubx_bmd360eval_nrf52811.dts:169 */

			/* node '/pin-controller/uart0_default/group1' defined in zephyr/boards/u-blox/ubx_bmd360eval/ubx_bmd360eval_nrf52811-pinctrl.dtsi:8 */
			group1 {
				psels = < 0x6 >,
				        < 0x1000008 >,
				        < 0x2000005 >,
				        < 0x3000007 >; /* in zephyr/boards/u-blox/ubx_bmd360eval/ubx_bmd360eval_nrf52811-pinctrl.dtsi:9 */
			};
		};

		/* node '/pin-controller/uart0_sleep' defined in zephyr/boards/u-blox/ubx_bmd360eval/ubx_bmd360eval_nrf52811-pinctrl.dtsi:16 */
		uart0_sleep: uart0_sleep {
			phandle = < 0x3 >; /* in zephyr/boards/u-blox/ubx_bmd360eval/ubx_bmd360eval_nrf52811.dts:170 */

			/* node '/pin-controller/uart0_sleep/group1' defined in zephyr/boards/u-blox/ubx_bmd360eval/ubx_bmd360eval_nrf52811-pinctrl.dtsi:17 */
			group1 {
				psels = < 0x6 >,
				        < 0x1000008 >,
				        < 0x2000005 >,
				        < 0x3000007 >; /* in zephyr/boards/u-blox/ubx_bmd360eval/ubx_bmd360eval_nrf52811-pinctrl.dtsi:18 */
				low-power-enable;      /* in zephyr/boards/u-blox/ubx_bmd360eval/ubx_bmd360eval_nrf52811-pinctrl.dtsi:22 */
			};
		};

		/* node '/pin-controller/i2c0_default' defined in zephyr/boards/u-blox/ubx_bmd360eval/ubx_bmd360eval_nrf52811-pinctrl.dtsi:26 */
		i2c0_default: i2c0_default {
			phandle = < 0x4 >; /* in zephyr/boards/u-blox/ubx_bmd360eval/ubx_bmd360eval_nrf52811.dts:178 */

			/* node '/pin-controller/i2c0_default/group1' defined in zephyr/boards/u-blox/ubx_bmd360eval/ubx_bmd360eval_nrf52811-pinctrl.dtsi:27 */
			group1 {
				psels = < 0xc00001a >,
				        < 0xb00001b >; /* in zephyr/boards/u-blox/ubx_bmd360eval/ubx_bmd360eval_nrf52811-pinctrl.dtsi:28 */
			};
		};

		/* node '/pin-controller/i2c0_sleep' defined in zephyr/boards/u-blox/ubx_bmd360eval/ubx_bmd360eval_nrf52811-pinctrl.dtsi:33 */
		i2c0_sleep: i2c0_sleep {
			phandle = < 0x5 >; /* in zephyr/boards/u-blox/ubx_bmd360eval/ubx_bmd360eval_nrf52811.dts:179 */

			/* node '/pin-controller/i2c0_sleep/group1' defined in zephyr/boards/u-blox/ubx_bmd360eval/ubx_bmd360eval_nrf52811-pinctrl.dtsi:34 */
			group1 {
				psels = < 0xc00001a >,
				        < 0xb00001b >; /* in zephyr/boards/u-blox/ubx_bmd360eval/ubx_bmd360eval_nrf52811-pinctrl.dtsi:35 */
				low-power-enable;      /* in zephyr/boards/u-blox/ubx_bmd360eval/ubx_bmd360eval_nrf52811-pinctrl.dtsi:37 */
			};
		};

		/* node '/pin-controller/pwm0_default' defined in zephyr/boards/u-blox/ubx_bmd360eval/ubx_bmd360eval_nrf52811-pinctrl.dtsi:41 */
		pwm0_default: pwm0_default {
			phandle = < 0x9 >; /* in zephyr/boards/u-blox/ubx_bmd360eval/ubx_bmd360eval_nrf52811.dts:185 */

			/* node '/pin-controller/pwm0_default/group1' defined in zephyr/boards/u-blox/ubx_bmd360eval/ubx_bmd360eval_nrf52811-pinctrl.dtsi:42 */
			group1 {
				psels = < 0x16000011 >; /* in zephyr/boards/u-blox/ubx_bmd360eval/ubx_bmd360eval_nrf52811-pinctrl.dtsi:43 */
				nordic,invert;          /* in zephyr/boards/u-blox/ubx_bmd360eval/ubx_bmd360eval_nrf52811-pinctrl.dtsi:44 */
			};
		};

		/* node '/pin-controller/pwm0_sleep' defined in zephyr/boards/u-blox/ubx_bmd360eval/ubx_bmd360eval_nrf52811-pinctrl.dtsi:48 */
		pwm0_sleep: pwm0_sleep {
			phandle = < 0xa >; /* in zephyr/boards/u-blox/ubx_bmd360eval/ubx_bmd360eval_nrf52811.dts:186 */

			/* node '/pin-controller/pwm0_sleep/group1' defined in zephyr/boards/u-blox/ubx_bmd360eval/ubx_bmd360eval_nrf52811-pinctrl.dtsi:49 */
			group1 {
				psels = < 0x16000011 >; /* in zephyr/boards/u-blox/ubx_bmd360eval/ubx_bmd360eval_nrf52811-pinctrl.dtsi:50 */
				low-power-enable;       /* in zephyr/boards/u-blox/ubx_bmd360eval/ubx_bmd360eval_nrf52811-pinctrl.dtsi:51 */
			};
		};

		/* node '/pin-controller/spi0_default' defined in zephyr/boards/u-blox/ubx_bmd360eval/ubx_bmd360eval_nrf52811-pinctrl.dtsi:55 */
		spi0_default: spi0_default {
			phandle = < 0x7 >; /* in zephyr/boards/u-blox/ubx_bmd360eval/ubx_bmd360eval_nrf52811.dts:194 */

			/* node '/pin-controller/spi0_default/group1' defined in zephyr/boards/u-blox/ubx_bmd360eval/ubx_bmd360eval_nrf52811-pinctrl.dtsi:56 */
			group1 {
				psels = < 0x4000019 >,
				        < 0x5000017 >,
				        < 0x6000018 >; /* in zephyr/boards/u-blox/ubx_bmd360eval/ubx_bmd360eval_nrf52811-pinctrl.dtsi:57 */
			};
		};

		/* node '/pin-controller/spi0_sleep' defined in zephyr/boards/u-blox/ubx_bmd360eval/ubx_bmd360eval_nrf52811-pinctrl.dtsi:63 */
		spi0_sleep: spi0_sleep {
			phandle = < 0x8 >; /* in zephyr/boards/u-blox/ubx_bmd360eval/ubx_bmd360eval_nrf52811.dts:195 */

			/* node '/pin-controller/spi0_sleep/group1' defined in zephyr/boards/u-blox/ubx_bmd360eval/ubx_bmd360eval_nrf52811-pinctrl.dtsi:64 */
			group1 {
				psels = < 0x4000019 >,
				        < 0x5000017 >,
				        < 0x6000018 >; /* in zephyr/boards/u-blox/ubx_bmd360eval/ubx_bmd360eval_nrf52811-pinctrl.dtsi:65 */
				low-power-enable;      /* in zephyr/boards/u-blox/ubx_bmd360eval/ubx_bmd360eval_nrf52811-pinctrl.dtsi:68 */
			};
		};
	};

	/* node '/entropy_bt_hci' defined in zephyr/dts/vendor/nordic/nrf_common.dtsi:34 */
	rng_hci: entropy_bt_hci {
		compatible = "zephyr,bt-hci-entropy"; /* in zephyr/dts/vendor/nordic/nrf_common.dtsi:35 */
		status = "disabled";                  /* in zephyr/dts/vendor/nordic/nrf_common.dtsi:36 */
	};

	/* node '/sw-pwm' defined in zephyr/dts/vendor/nordic/nrf_common.dtsi:39 */
	sw_pwm: sw-pwm {
		compatible = "nordic,nrf-sw-pwm"; /* in zephyr/dts/vendor/nordic/nrf_common.dtsi:40 */
		status = "disabled";              /* in zephyr/dts/vendor/nordic/nrf_common.dtsi:41 */
		generator = < &timer1 >;          /* in zephyr/dts/vendor/nordic/nrf_common.dtsi:42 */
		clock-prescaler = < 0x0 >;        /* in zephyr/dts/vendor/nordic/nrf_common.dtsi:43 */
		#pwm-cells = < 0x3 >;             /* in zephyr/dts/vendor/nordic/nrf_common.dtsi:44 */
	};

	/* node '/cpus' defined in zephyr/dts/arm/nordic/nrf52811.dtsi:19 */
	cpus {
		#address-cells = < 0x1 >; /* in zephyr/dts/arm/nordic/nrf52811.dtsi:20 */
		#size-cells = < 0x0 >;    /* in zephyr/dts/arm/nordic/nrf52811.dtsi:21 */

		/* node '/cpus/cpu@0' defined in zephyr/dts/arm/nordic/nrf52811.dtsi:23 */
		cpu@0 {
			device_type = "cpu";          /* in zephyr/dts/arm/nordic/nrf52811.dtsi:24 */
			compatible = "arm,cortex-m4"; /* in zephyr/dts/arm/nordic/nrf52811.dtsi:25 */
			reg = < 0x0 >;                /* in zephyr/dts/arm/nordic/nrf52811.dtsi:26 */
			#address-cells = < 0x1 >;     /* in zephyr/dts/arm/nordic/nrf52811.dtsi:27 */
			#size-cells = < 0x1 >;        /* in zephyr/dts/arm/nordic/nrf52811.dtsi:28 */

			/* node '/cpus/cpu@0/itm@e0000000' defined in zephyr/dts/arm/nordic/nrf52811.dtsi:30 */
			itm: itm@e0000000 {
				compatible = "arm,armv7m-itm";     /* in zephyr/dts/arm/nordic/nrf52811.dtsi:31 */
				reg = < 0xe0000000 0x1000 >;       /* in zephyr/dts/arm/nordic/nrf52811.dtsi:32 */
				swo-ref-frequency = < 0x1e84800 >; /* in zephyr/dts/arm/nordic/nrf52811.dtsi:33 */
			};
		};
	};

	/* node '/clocks' defined in zephyr/dts/arm/nordic/nrf52811.dtsi:38 */
	clocks {

		/* node '/clocks/hfxo' defined in zephyr/dts/arm/nordic/nrf52811.dtsi:39 */
		hfxo: hfxo {
			compatible = "nordic,nrf52-hfxo"; /* in zephyr/dts/arm/nordic/nrf52811.dtsi:40 */
			clock-frequency = < 0x3d09000 >;  /* in zephyr/dts/arm/nordic/nrf52811.dtsi:41 */
			startup-time-us = < 0x578 >;      /* in zephyr/dts/arm/nordic/nrf52811.dtsi:42 */
			#clock-cells = < 0x0 >;           /* in zephyr/dts/arm/nordic/nrf52811.dtsi:43 */
		};
	};

	/* node '/leds' defined in zephyr/boards/u-blox/ubx_bmd360eval/ubx_bmd360eval_nrf52811.dts:28 */
	leds {
		compatible = "gpio-leds"; /* in zephyr/boards/u-blox/ubx_bmd360eval/ubx_bmd360eval_nrf52811.dts:29 */

		/* node '/leds/led_0' defined in zephyr/boards/u-blox/ubx_bmd360eval/ubx_bmd360eval_nrf52811.dts:31 */
		led0: led_0 {
			gpios = < &gpio0 0x11 0x1 >; /* in zephyr/boards/u-blox/ubx_bmd360eval/ubx_bmd360eval_nrf52811.dts:32 */
			label = "Red LED 0";         /* in zephyr/boards/u-blox/ubx_bmd360eval/ubx_bmd360eval_nrf52811.dts:33 */
		};

		/* node '/leds/led_1' defined in zephyr/boards/u-blox/ubx_bmd360eval/ubx_bmd360eval_nrf52811.dts:36 */
		led1: led_1 {
			gpios = < &gpio0 0x12 0x1 >; /* in zephyr/boards/u-blox/ubx_bmd360eval/ubx_bmd360eval_nrf52811.dts:37 */
			label = "Red LED 1";         /* in zephyr/boards/u-blox/ubx_bmd360eval/ubx_bmd360eval_nrf52811.dts:38 */
		};

		/* node '/leds/led_2' defined in zephyr/boards/u-blox/ubx_bmd360eval/ubx_bmd360eval_nrf52811.dts:41 */
		led2: led_2 {
			gpios = < &gpio0 0x13 0x1 >; /* in zephyr/boards/u-blox/ubx_bmd360eval/ubx_bmd360eval_nrf52811.dts:42 */
			label = "Green LED 2";       /* in zephyr/boards/u-blox/ubx_bmd360eval/ubx_bmd360eval_nrf52811.dts:43 */
		};

		/* node '/leds/led_3' defined in zephyr/boards/u-blox/ubx_bmd360eval/ubx_bmd360eval_nrf52811.dts:46 */
		led3: led_3 {
			gpios = < &gpio0 0x14 0x1 >; /* in zephyr/boards/u-blox/ubx_bmd360eval/ubx_bmd360eval_nrf52811.dts:47 */
			label = "Green LED 3";       /* in zephyr/boards/u-blox/ubx_bmd360eval/ubx_bmd360eval_nrf52811.dts:48 */
		};
	};

	/* node '/pwmleds' defined in zephyr/boards/u-blox/ubx_bmd360eval/ubx_bmd360eval_nrf52811.dts:52 */
	pwmleds {
		compatible = "pwm-leds"; /* in zephyr/boards/u-blox/ubx_bmd360eval/ubx_bmd360eval_nrf52811.dts:53 */

		/* node '/pwmleds/pwm_led_0' defined in zephyr/boards/u-blox/ubx_bmd360eval/ubx_bmd360eval_nrf52811.dts:55 */
		pwm_led0: pwm_led_0 {
			pwms = < &pwm0 0x0 0x1312d00 0x1 >; /* in zephyr/boards/u-blox/ubx_bmd360eval/ubx_bmd360eval_nrf52811.dts:56 */
		};
	};

	/* node '/buttons' defined in zephyr/boards/u-blox/ubx_bmd360eval/ubx_bmd360eval_nrf52811.dts:60 */
	buttons {
		compatible = "gpio-keys"; /* in zephyr/boards/u-blox/ubx_bmd360eval/ubx_bmd360eval_nrf52811.dts:61 */

		/* node '/buttons/button_0' defined in zephyr/boards/u-blox/ubx_bmd360eval/ubx_bmd360eval_nrf52811.dts:63 */
		button0: button_0 {
			gpios = < &gpio0 0xd 0x11 >;    /* in zephyr/boards/u-blox/ubx_bmd360eval/ubx_bmd360eval_nrf52811.dts:64 */
			label = "Push button switch 0"; /* in zephyr/boards/u-blox/ubx_bmd360eval/ubx_bmd360eval_nrf52811.dts:65 */
			zephyr,code = < 0xb >;          /* in zephyr/boards/u-blox/ubx_bmd360eval/ubx_bmd360eval_nrf52811.dts:66 */
		};

		/* node '/buttons/button_1' defined in zephyr/boards/u-blox/ubx_bmd360eval/ubx_bmd360eval_nrf52811.dts:69 */
		button1: button_1 {
			gpios = < &gpio0 0xe 0x11 >;    /* in zephyr/boards/u-blox/ubx_bmd360eval/ubx_bmd360eval_nrf52811.dts:70 */
			label = "Push button switch 1"; /* in zephyr/boards/u-blox/ubx_bmd360eval/ubx_bmd360eval_nrf52811.dts:71 */
			zephyr,code = < 0x2 >;          /* in zephyr/boards/u-blox/ubx_bmd360eval/ubx_bmd360eval_nrf52811.dts:72 */
		};

		/* node '/buttons/button_2' defined in zephyr/boards/u-blox/ubx_bmd360eval/ubx_bmd360eval_nrf52811.dts:75 */
		button2: button_2 {
			gpios = < &gpio0 0xf 0x11 >;    /* in zephyr/boards/u-blox/ubx_bmd360eval/ubx_bmd360eval_nrf52811.dts:76 */
			label = "Push button switch 2"; /* in zephyr/boards/u-blox/ubx_bmd360eval/ubx_bmd360eval_nrf52811.dts:77 */
			zephyr,code = < 0x3 >;          /* in zephyr/boards/u-blox/ubx_bmd360eval/ubx_bmd360eval_nrf52811.dts:78 */
		};

		/* node '/buttons/button_3' defined in zephyr/boards/u-blox/ubx_bmd360eval/ubx_bmd360eval_nrf52811.dts:81 */
		button3: button_3 {
			gpios = < &gpio0 0x10 0x11 >;   /* in zephyr/boards/u-blox/ubx_bmd360eval/ubx_bmd360eval_nrf52811.dts:82 */
			label = "Push button switch 3"; /* in zephyr/boards/u-blox/ubx_bmd360eval/ubx_bmd360eval_nrf52811.dts:83 */
			zephyr,code = < 0x4 >;          /* in zephyr/boards/u-blox/ubx_bmd360eval/ubx_bmd360eval_nrf52811.dts:84 */
		};
	};

	/* node '/connector' defined in zephyr/boards/u-blox/ubx_bmd360eval/ubx_bmd360eval_nrf52811.dts:88 */
	arduino_header: connector {
		compatible = "arduino-header-r3";          /* in zephyr/boards/u-blox/ubx_bmd360eval/ubx_bmd360eval_nrf52811.dts:89 */
		#gpio-cells = < 0x2 >;                     /* in zephyr/boards/u-blox/ubx_bmd360eval/ubx_bmd360eval_nrf52811.dts:90 */
		gpio-map-mask = < 0xffffffff 0xffffffc0 >; /* in zephyr/boards/u-blox/ubx_bmd360eval/ubx_bmd360eval_nrf52811.dts:91 */
		gpio-map-pass-thru = < 0x0 0x3f >;         /* in zephyr/boards/u-blox/ubx_bmd360eval/ubx_bmd360eval_nrf52811.dts:92 */
		gpio-map = < 0x0 0x0 &gpio0 0x3 0x0 >,
		           < 0x1 0x0 &gpio0 0x4 0x0 >,
		           < 0x2 0x0 &gpio0 0x1c 0x0 >,
		           < 0x3 0x0 &gpio0 0x1d 0x0 >,
		           < 0x4 0x0 &gpio0 0x1e 0x0 >,
		           < 0x5 0x0 &gpio0 0x1f 0x0 >,
		           < 0x6 0x0 &gpio0 0xb 0x0 >,
		           < 0x7 0x0 &gpio0 0xc 0x0 >,
		           < 0x8 0x0 &gpio0 0xd 0x0 >,
		           < 0x9 0x0 &gpio0 0xe 0x0 >,
		           < 0xa 0x0 &gpio0 0xf 0x0 >,
		           < 0xb 0x0 &gpio0 0x10 0x0 >,
		           < 0xc 0x0 &gpio0 0x11 0x0 >,
		           < 0xd 0x0 &gpio0 0x12 0x0 >,
		           < 0xe 0x0 &gpio0 0x13 0x0 >,
		           < 0xf 0x0 &gpio0 0x14 0x0 >,
		           < 0x10 0x0 &gpio0 0x16 0x0 >,
		           < 0x11 0x0 &gpio0 0x17 0x0 >,
		           < 0x12 0x0 &gpio0 0x18 0x0 >,
		           < 0x13 0x0 &gpio0 0x19 0x0 >,
		           < 0x14 0x0 &gpio0 0x1a 0x0 >,
		           < 0x15 0x0 &gpio0 0x1b 0x0 >;   /* in zephyr/boards/u-blox/ubx_bmd360eval/ubx_bmd360eval_nrf52811.dts:93 */
		phandle = < 0x6 >;                         /* in zephyr/boards/u-blox/ubx_bmd360eval/ubx_bmd360eval_nrf52811.dts:193 */
	};

	/* node '/analog-connector' defined in zephyr/boards/u-blox/ubx_bmd360eval/ubx_bmd360eval_nrf52811.dts:117 */
	arduino_adc: analog-connector {
		compatible = "arduino,uno-adc";    /* in zephyr/boards/u-blox/ubx_bmd360eval/ubx_bmd360eval_nrf52811.dts:118 */
		#io-channel-cells = < 0x1 >;       /* in zephyr/boards/u-blox/ubx_bmd360eval/ubx_bmd360eval_nrf52811.dts:119 */
		io-channel-map = < 0x0 &adc 0x1 >,
		                 < 0x1 &adc 0x2 >,
		                 < 0x2 &adc 0x4 >,
		                 < 0x3 &adc 0x5 >,
		                 < 0x4 &adc 0x6 >,
		                 < 0x5 &adc 0x7 >; /* in zephyr/boards/u-blox/ubx_bmd360eval/ubx_bmd360eval_nrf52811.dts:120 */
	};
};
